# STM32H745BGT6@M4 register map
File version: 1.0
Registers are 32-bit, access not given, reset 0x0 unless marked. A register's access mark holds for its fields unless they carry their own. Offsets are from the block's base; [hi:lo] are bit positions; 'fields as' and 'values as' point back to an identical list.

## FLASH
Base 0x52002000
0x04 KEYR1
  [31:0] KEY1R
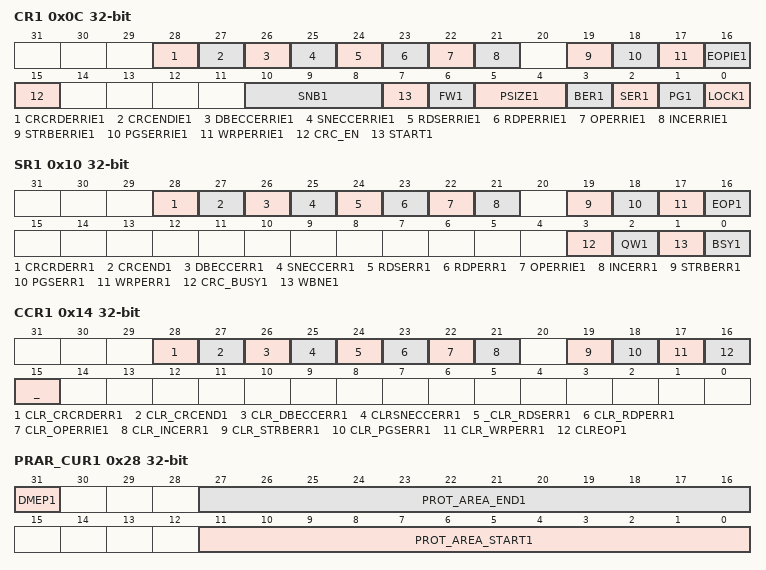
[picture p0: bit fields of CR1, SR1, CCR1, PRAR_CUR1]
0x0C CR1
  [28] CRCRDERRIE1, [27] CRCENDIE1, [26] DBECCERRIE1, [25] SNECCERRIE1, [24] RDSERRIE1, [23] RDPERRIE1, [22] OPERRIE1, [21] INCERRIE1, [19] STRBERRIE1, [18] PGSERRIE1, [17] WRPERRIE1, [16] EOPIE1, [15] CRC_EN, [10:8] SNB1, [7] START1, [6] FW1, [5:4] PSIZE1, [3] BER1, [2] SER1, [1] PG1, [0] LOCK1
0x10 SR1
  [28] CRCRDERR1, [27] CRCEND1, [26] DBECCERR1, [25] SNECCERR1, [24] RDSERR1, [23] RDPERR1, [22] OPERRIE1, [21] INCERR1, [19] STRBERR1, [18] PGSERR1, [17] WRPERR1, [16] EOP1, [3] CRC_BUSY1, [2] QW1, [1] WBNE1, [0] BSY1
0x14 CCR1
  [28] CLR_CRCRDERR1, [27] CLR_CRCEND1, [26] CLR_DBECCERR1, [25] CLRSNECCERR1, [24] _CLR_RDSERR1, [23] CLR_RDPERR1, [22] CLR_OPERRIE1, [21] CLR_INCERR1, [19] CLR_STRBERR1, [18] CLR_PGSERR1, [17] CLR_WRPERR1, [16] CLREOP1, [15] _
0x28 PRAR_CUR1
  [31] DMEP1, [27:16] PROT_AREA_END1, [11:0] PROT_AREA_START1
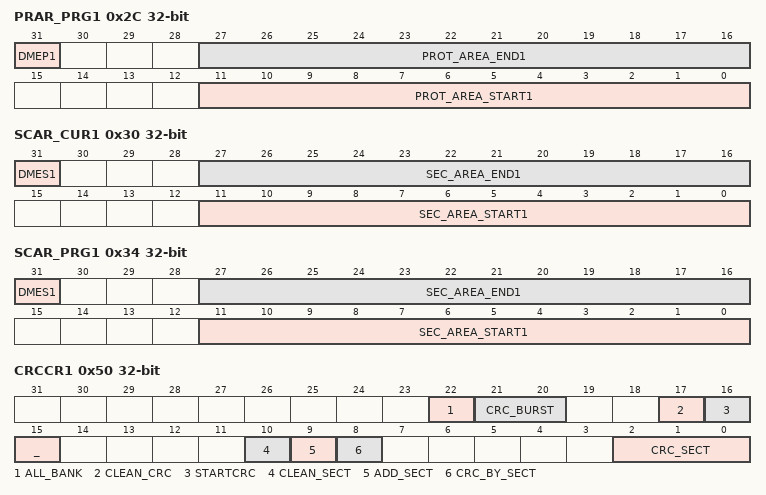
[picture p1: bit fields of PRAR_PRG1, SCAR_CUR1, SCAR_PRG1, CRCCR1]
0x2C PRAR_PRG1
  [31] DMEP1, [27:16] PROT_AREA_END1, [11:0] PROT_AREA_START1
0x30 SCAR_CUR1
  [31] DMES1, [27:16] SEC_AREA_END1, [11:0] SEC_AREA_START1
0x34 SCAR_PRG1
  [31] DMES1, [27:16] SEC_AREA_END1, [11:0] SEC_AREA_START1
0x38 WPSN_CUR1R
  [7:0] WRPSn1
0x3C WPSN_PRG1R
  [7:0] WRPSn1
0x50 CRCCR1
  [22] ALL_BANK, [21:20] CRC_BURST, [17] CLEAN_CRC, [16] STARTCRC, [15] _, [10] CLEAN_SECT, [9] ADD_SECT, [8] CRC_BY_SECT, [2:0] CRC_SECT
0x54 CRCSADD1R
  [19:2] CRC_START_ADDR
0x58 CRCEADD1R
  [19:2] CRC_END_ADDR
0x60 ECC_FA1R
  [14:0] FAIL_ECC_ADDR1
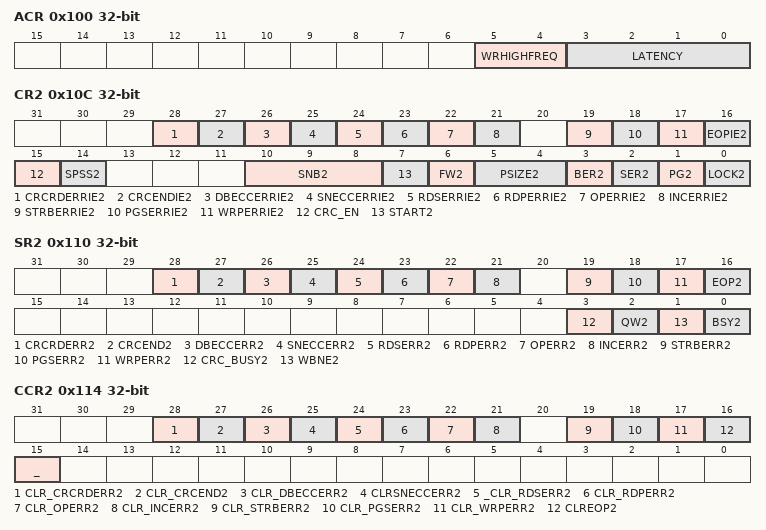
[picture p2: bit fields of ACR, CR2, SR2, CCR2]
0x100 ACR
  [5:4] WRHIGHFREQ, [3:0] LATENCY
0x104 KEYR2
  [31:0] KEY2R
0x108 OPTKEYR
0x10C CR2
  [28] CRCRDERRIE2, [27] CRCENDIE2, [26] DBECCERRIE2, [25] SNECCERRIE2, [24] RDSERRIE2, [23] RDPERRIE2, [22] OPERRIE2, [21] INCERRIE2, [19] STRBERRIE2, [18] PGSERRIE2, [17] WRPERRIE2, [16] EOPIE2, [15] CRC_EN, [14] SPSS2, [10:8] SNB2, [7] START2, [6] FW2, [5:4] PSIZE2, [3] BER2, [2] SER2, [1] PG2, [0] LOCK2
0x110 SR2
  [28] CRCRDERR2, [27] CRCEND2, [26] DBECCERR2, [25] SNECCERR2, [24] RDSERR2, [23] RDPERR2, [22] OPERR2, [21] INCERR2, [19] STRBERR2, [18] PGSERR2, [17] WRPERR2, [16] EOP2, [3] CRC_BUSY2, [2] QW2, [1] WBNE2, [0] BSY2
0x114 CCR2
  [28] CLR_CRCRDERR2, [27] CLR_CRCEND2, [26] CLR_DBECCERR2, [25] CLRSNECCERR2, [24] _CLR_RDSERR2, [23] CLR_RDPERR2, [22] CLR_OPERR2, [21] CLR_INCERR2, [19] CLR_STRBERR2, [18] CLR_PGSERR2, [17] CLR_WRPERR2, [16] CLREOP2, [15] _
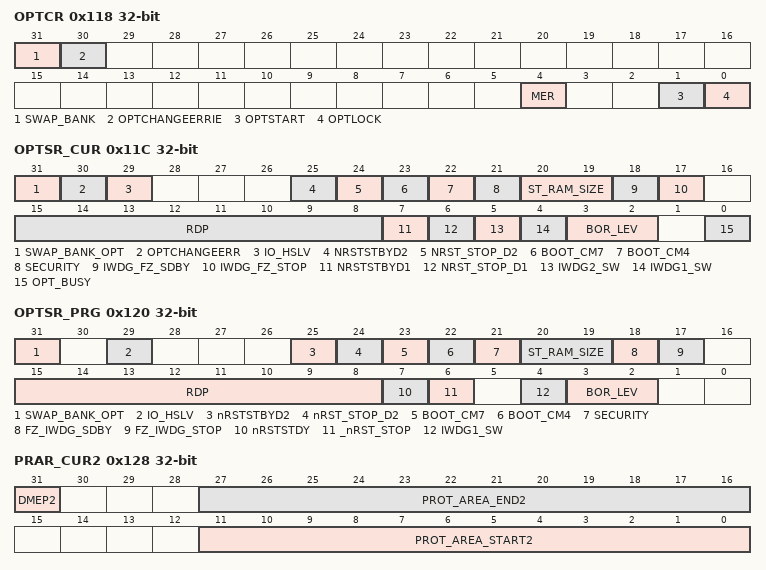
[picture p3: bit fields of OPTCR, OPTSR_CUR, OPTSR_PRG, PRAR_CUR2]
0x118 OPTCR
  [31] SWAP_BANK, [30] OPTCHANGEERRIE, [4] MER, [1] OPTSTART, [0] OPTLOCK
0x11C OPTSR_CUR
  [31] SWAP_BANK_OPT, [30] OPTCHANGEERR, [29] IO_HSLV, [25] NRSTSTBYD2, [24] NRST_STOP_D2, [23] BOOT_CM7, [22] BOOT_CM4, [21] SECURITY, [20:19] ST_RAM_SIZE, [18] IWDG_FZ_SDBY, [17] IWDG_FZ_STOP, [15:8] RDP, [7] NRSTSTBYD1, [6] NRST_STOP_D1, [5] IWDG2_SW, [4] IWDG1_SW, [3:2] BOR_LEV, [0] OPT_BUSY
0x120 OPTSR_PRG
  [31] SWAP_BANK_OPT, [29] IO_HSLV, [25] nRSTSTBYD2, [24] nRST_STOP_D2, [23] BOOT_CM7, [22] BOOT_CM4, [21] SECURITY, [20:19] ST_RAM_SIZE, [18] FZ_IWDG_SDBY, [17] FZ_IWDG_STOP, [15:8] RDP, [7] nRSTSTDY, [6] _nRST_STOP, [4] IWDG1_SW, [3:2] BOR_LEV
0x124 OPTCCR
  [30] CLR_OPTCHANGEERR
0x128 PRAR_CUR2
  [31] DMEP2, [27:16] PROT_AREA_END2, [11:0] PROT_AREA_START2
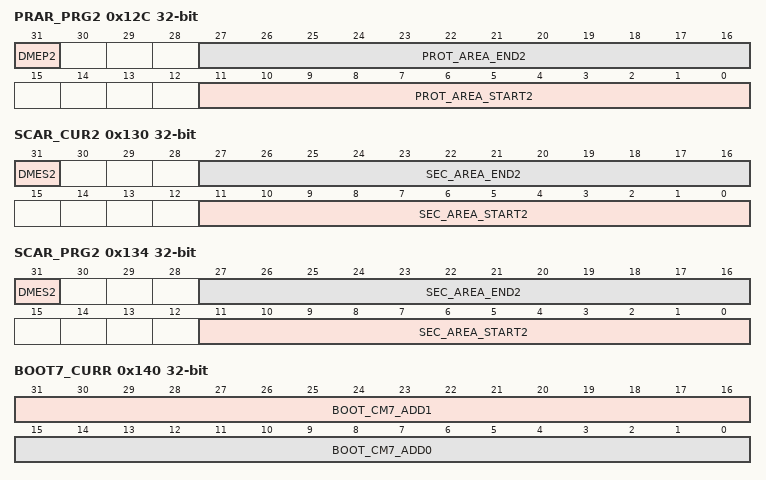
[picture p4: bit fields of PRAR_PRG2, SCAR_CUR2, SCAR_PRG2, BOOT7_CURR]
0x12C PRAR_PRG2
  [31] DMEP2, [27:16] PROT_AREA_END2, [11:0] PROT_AREA_START2
0x130 SCAR_CUR2
  [31] DMES2, [27:16] SEC_AREA_END2, [11:0] SEC_AREA_START2
0x134 SCAR_PRG2
  [31] DMES2, [27:16] SEC_AREA_END2, [11:0] SEC_AREA_START2
0x138 WPSN_CUR2R
  [7:0] WRPSn2
0x13C WPSN_PRG2R
  [7:0] WRPSn2
0x140 BOOT7_CURR
  [31:16] BOOT_CM7_ADD1, [15:0] BOOT_CM7_ADD0
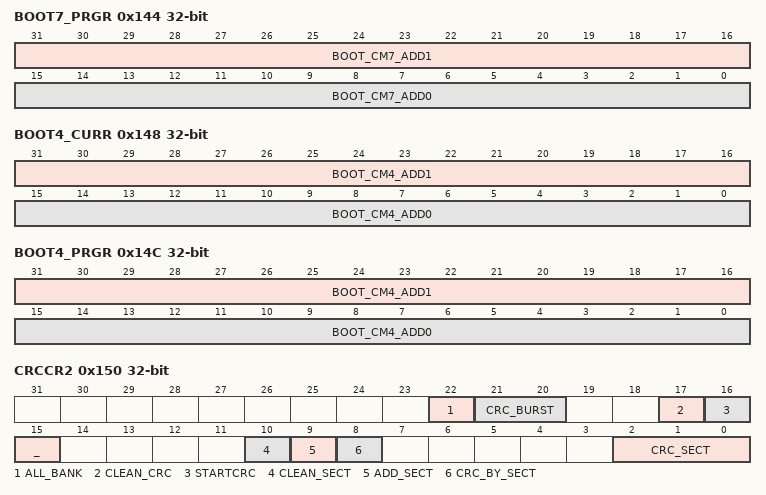
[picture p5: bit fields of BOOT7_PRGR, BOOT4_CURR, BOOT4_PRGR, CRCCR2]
0x144 BOOT7_PRGR
  [31:16] BOOT_CM7_ADD1, [15:0] BOOT_CM7_ADD0
0x148 BOOT4_CURR
  [31:16] BOOT_CM4_ADD1, [15:0] BOOT_CM4_ADD0
0x14C BOOT4_PRGR
  [31:16] BOOT_CM4_ADD1, [15:0] BOOT_CM4_ADD0
0x150 CRCCR2
  fields as CRCCR1
0x154 CRCSADD2R
  [19:2] CRC_START_ADDR
0x158 CRCEADD2R
  [19:2] CRC_END_ADDR
0x15C CRCDATAR
  [31:0] CRC_DATA
0x160 ECC_FA2R
  [15:0] FAIL_ECC_ADDR2
